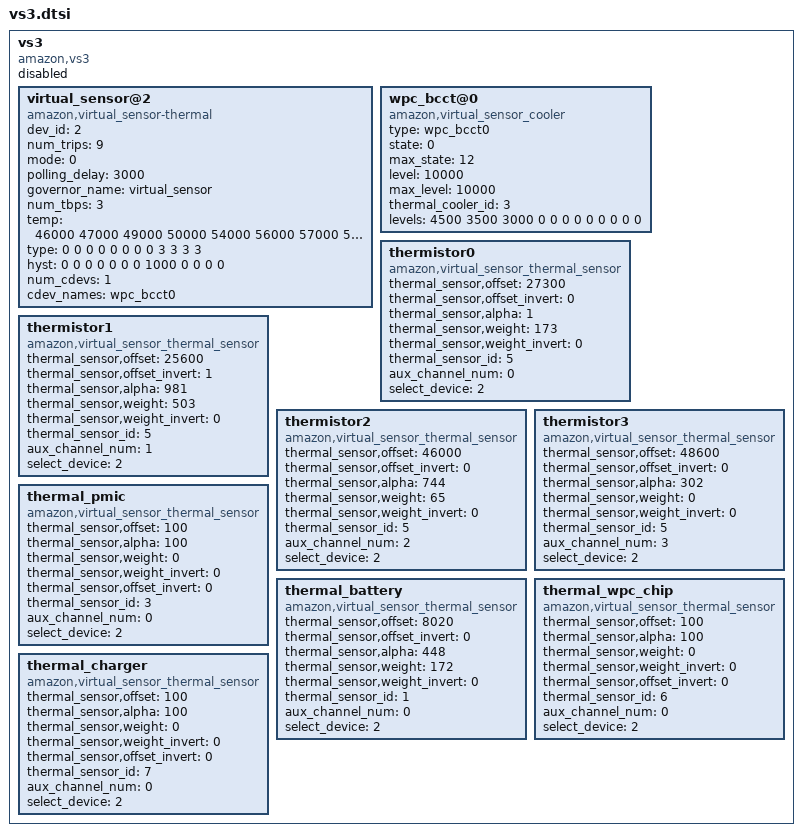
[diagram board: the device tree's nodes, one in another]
/*
 * Copyright (C) 2019-2020 Amazon Technologies Inc. All rights reserved.
 *
 * This program is free software; you can redistribute it and/or modify
 * it under the terms of the GNU General Public License version 2 as
 * published by the Free Software Foundation.
 *
 * This program is distributed in the hope that it will be useful,
 * MERCHANTABILITY or FITNESS FOR A PARTICULAR PURPOSE.  See the
 * GNU General Public License for more details.
 */

/*
 * Virtual sensor
 * select_device: Decide to register which thermal_zone device
 * 0: register to thermal_zone9, 1: register to thermal_zone10
 */

vs3: vs3 {
	status = "disabled";
	compatible = "amazon,vs3", "simple-bus";

	virtual_sensor@2{
		compatible = "amazon,virtual_sensor-thermal";
		dev_id = <2>;
		num_trips = <9>;
		mode = <0>;
		polling_delay = <3000>;
		governor_name = "virtual_sensor";
		num_tbps = <3>;
		temp = <46000 47000 49000 50000 54000 56000 57000 58000 60000 60000 60000 60000>;
		type = <0 0 0 0 0 0 0 0 3 3 3 3>;
		hyst = <0 0 0 0 0 0 0 1000 0 0 0 0>;
		num_cdevs = <1>;
		cdev_names = "wpc_bcct0";
	};

	wpc_bcct@0 {
		compatible = "amazon,virtual_sensor_cooler";
		type = "wpc_bcct0";
		state = <0>;
		max_state = <12>;
		level = <10000>;
		max_level = <10000>;
		thermal_cooler_id = <3>;
		levels = <4500 3500 3000 0 0 0 0 0 0 0 0 0>;
	};

	/* Virtual sensor thermistor */
	thermistor0 {
		compatible = "amazon,virtual_sensor_thermal_sensor";
		thermal_sensor,offset = <27300>;
		thermal_sensor,offset_invert = <0>;
		thermal_sensor,alpha = <1>;
		thermal_sensor,weight = <173>;
		thermal_sensor,weight_invert = <0>;
		thermal_sensor_id = <5>;
		aux_channel_num = <0>;
		select_device = <2>;
	};

	thermistor1 {
		compatible = "amazon,virtual_sensor_thermal_sensor";
		thermal_sensor,offset = <25600>;
		thermal_sensor,offset_invert = <1>;
		thermal_sensor,alpha = <981>;
		thermal_sensor,weight = <503>;
		thermal_sensor,weight_invert = <0>;
		thermal_sensor_id = <5>;
		aux_channel_num = <1>;
		select_device = <2>;
	};

	thermistor2 {
		compatible = "amazon,virtual_sensor_thermal_sensor";
		thermal_sensor,offset = <46000>;
		thermal_sensor,offset_invert = <0>;
		thermal_sensor,alpha = <744>;
		thermal_sensor,weight = <65>;
		thermal_sensor,weight_invert = <0>;
		thermal_sensor_id = <5>;
		aux_channel_num = <2>;
		select_device = <2>;
	};

	thermistor3 {
		compatible = "amazon,virtual_sensor_thermal_sensor";
		thermal_sensor,offset = <48600>;
		thermal_sensor,offset_invert = <0>;
		thermal_sensor,alpha = <302>;
		thermal_sensor,weight = <0>;
		thermal_sensor,weight_invert = <0>;
		thermal_sensor_id = <5>;
		aux_channel_num = <3>;
		select_device = <2>;
	};

	thermal_pmic {
		compatible = "amazon,virtual_sensor_thermal_sensor";
		thermal_sensor,offset = <100>;
		thermal_sensor,alpha = <100>;
		thermal_sensor,weight = <0>;
		thermal_sensor,weight_invert = <0>;
		thermal_sensor,offset_invert = <0>;
		thermal_sensor_id = <3>;
		aux_channel_num = <0>;
		select_device = <2>;
	};
	thermal_battery {
		compatible = "amazon,virtual_sensor_thermal_sensor";
		thermal_sensor,offset = <8020>;
		thermal_sensor,offset_invert = <0>;
		thermal_sensor,alpha = <448>;
		thermal_sensor,weight = <172>;
		thermal_sensor,weight_invert = <0>;
		thermal_sensor_id = <1>;
		aux_channel_num = <0>;
		select_device = <2>;
	};
	thermal_wpc_chip {
		compatible = "amazon,virtual_sensor_thermal_sensor";
		thermal_sensor,offset = <100>;
		thermal_sensor,alpha = <100>;
		thermal_sensor,weight = <0>;
		thermal_sensor,weight_invert = <0>;
		thermal_sensor,offset_invert = <0>;
		thermal_sensor_id = <6>;
		aux_channel_num = <0>;
		select_device = <2>;
	};
	thermal_charger {
		compatible = "amazon,virtual_sensor_thermal_sensor";
		thermal_sensor,offset = <100>;
		thermal_sensor,alpha = <100>;
		thermal_sensor,weight = <0>;
		thermal_sensor,weight_invert = <0>;
		thermal_sensor,offset_invert = <0>;
		thermal_sensor_id = <7>;
		aux_channel_num = <0>;
		select_device = <2>;
	};
};
